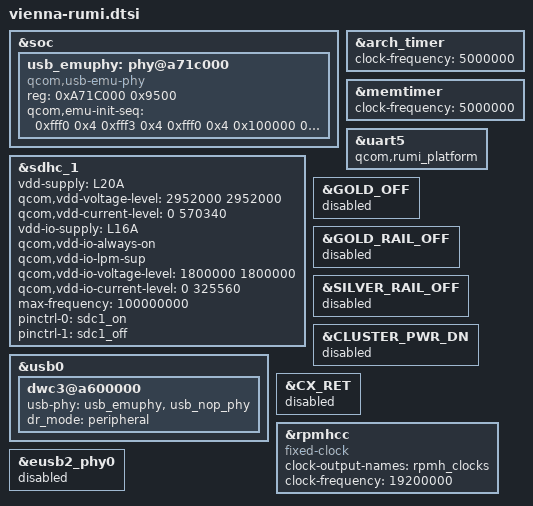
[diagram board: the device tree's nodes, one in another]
// SPDX-License-Identifier: BSD-3-Clause
/*
 * Copyright (c) 2024-2025, Qualcomm Innovation Center, Inc. All rights reserved.
 */

#include <dt-bindings/clock/qcom,gcc-vienna.h>

&soc {
	usb_emuphy: phy@a71c000 {
		compatible = "qcom,usb-emu-phy";
		reg = <0xA71C000 0x9500>;

		qcom,emu-init-seq = <0xfff0 0x4
					0xfff3 0x4
					0xfff0 0x4
					0x100000 0x20
					0x0 0x20
					0x1e0 0x20
					0x100000 0x3c
					0x0 0x3c
					0x4 0x3c
					0x0 0x4
					0x9 0x14>;
	};
};

&arch_timer {
	clock-frequency = <5000000>;
};

&memtimer {
	clock-frequency = <5000000>;
};

&sdhc_1 {
	status = "okay";
	vdd-supply = <&L20A>;
	qcom,vdd-voltage-level = <2952000 2952000>;
	qcom,vdd-current-level = <0 570340>;

	vdd-io-supply = <&L16A>;
	qcom,vdd-io-always-on;
	qcom,vdd-io-lpm-sup;
	qcom,vdd-io-voltage-level = <1800000 1800000>;
	qcom,vdd-io-current-level = <0 325560>;

	/delete-property/ mmc-ddr-1_8v;
	/delete-property/ mmc-hs200-1_8v;
	/delete-property/ mmc-hs400-1_8v;
	/delete-property/ mmc-hs400-enhanced-strobe;

	max-frequency = <100000000>;

	pinctrl-names = "default", "sleep";
	pinctrl-0 = <&sdc1_on>;
	pinctrl-1 = <&sdc1_off>;
};

&uart5 {
	qcom,rumi_platform;
	status = "ok";
};

&usb0 {
	dwc3@a600000 {
		usb-phy = <&usb_emuphy>, <&usb_nop_phy>;
		dr_mode = "peripheral";
	};
};

&GOLD_OFF {
	status = "disabled";
};

&GOLD_RAIL_OFF {
	status = "disabled";
};

&SILVER_RAIL_OFF {
	status = "disabled";
};

&CLUSTER_PWR_DN {
	status = "disabled";
};

&CX_RET {
	status = "disabled";
};

&rpmhcc {
	compatible = "fixed-clock";
	clock-output-names = "rpmh_clocks";
	clock-frequency = <19200000>;
};

&eusb2_phy0 {
	status = "disabled";
};
